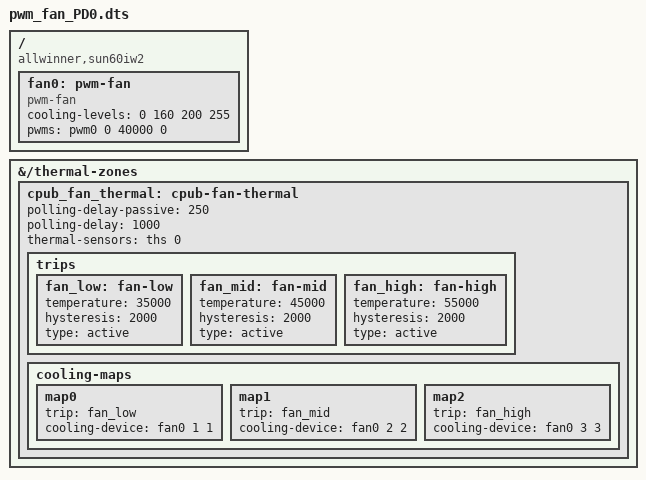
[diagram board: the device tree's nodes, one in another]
/dts-v1/;
/plugin/;

/ {
    compatible = "allwinner,sun60iw2", "allwinner,sunxi";

    fragment@0 {
        target-path = "/";
        __overlay__ {
            fan0: pwm-fan {
                compatible = "pwm-fan";
                #cooling-cells = <2>;
                cooling-levels = <0 160 200 255>;
                pwms = <&pwm0 0 40000 0>;
                status = "okay";
            };
        };
    };
/* 3. Создаем НОВУЮ термозону для управления вентилятором */
    fragment@1 {
        target-path = "/thermal-zones";
        __overlay__ {
            cpub_fan_thermal: cpub-fan-thermal {
                polling-delay-passive = <250>;
                polling-delay = <1000>;

                /* Привязываемся к аппаратному датчику температуры процессора */
                /* Проверьте точную метку ths или tsensor в вашей системе, обычно это &ths */
                thermal-sensors = <&ths 0>; 

                trips {
                    fan_low: fan-low {
                        temperature = <35000>; /* 45°C */
                        hysteresis = <2000>;
                        type = "active";
                    };
                    fan_mid: fan-mid {
                        temperature = <45000>; /* 55°C */
                        hysteresis = <2000>;
                        type = "active";
                    };
                    fan_high: fan-high {
                        temperature = <55000>; /* 65°C */
                        hysteresis = <2000>;
                        type = "active";
                    };
                };

                cooling-maps {
                    map0 {
                        trip = <&fan_low>;
                        cooling-device = <&fan0 1 1>;
                    };
                    map1 {
                        trip = <&fan_mid>;
                        cooling-device = <&fan0 2 2>;
                    };
                    map2 {
                        trip = <&fan_high>;
                        cooling-device = <&fan0 3 3>;
                    };
                };
            };
        };
    };
};
